# iorx65n register map
Registers are 8-bit, access not given, no defined reset value unless marked. A register's access mark holds for its fields unless they carry their own. Addresses are absolute; registers are grouped by the start of their names; [hi:lo] are bit positions.

## SFR (part 5 of 7)
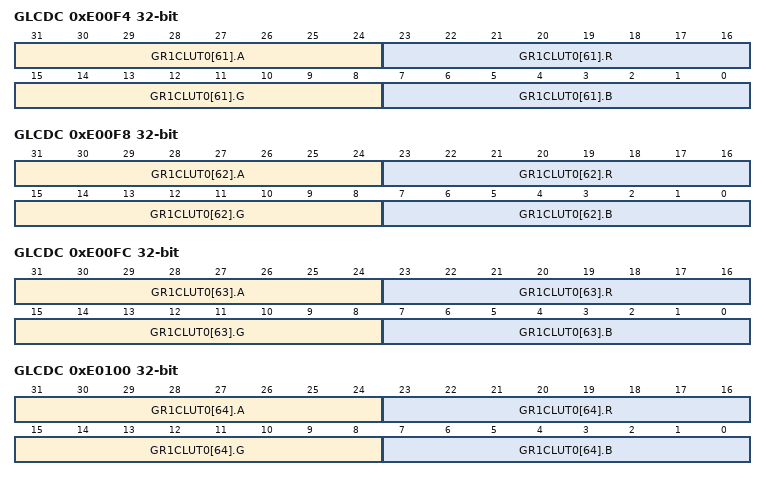
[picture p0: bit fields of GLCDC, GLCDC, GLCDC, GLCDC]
0xE00F4 GLCDC 32-bit
  [31:24] GR1CLUT0[61].A, [23:16] GR1CLUT0[61].R, [15:8] GR1CLUT0[61].G, [7:0] GR1CLUT0[61].B
0xE00F8 GLCDC 32-bit
  [31:24] GR1CLUT0[62].A, [23:16] GR1CLUT0[62].R, [15:8] GR1CLUT0[62].G, [7:0] GR1CLUT0[62].B
0xE00FC GLCDC 32-bit
  [31:24] GR1CLUT0[63].A, [23:16] GR1CLUT0[63].R, [15:8] GR1CLUT0[63].G, [7:0] GR1CLUT0[63].B
0xE0100 GLCDC 32-bit
  [31:24] GR1CLUT0[64].A, [23:16] GR1CLUT0[64].R, [15:8] GR1CLUT0[64].G, [7:0] GR1CLUT0[64].B
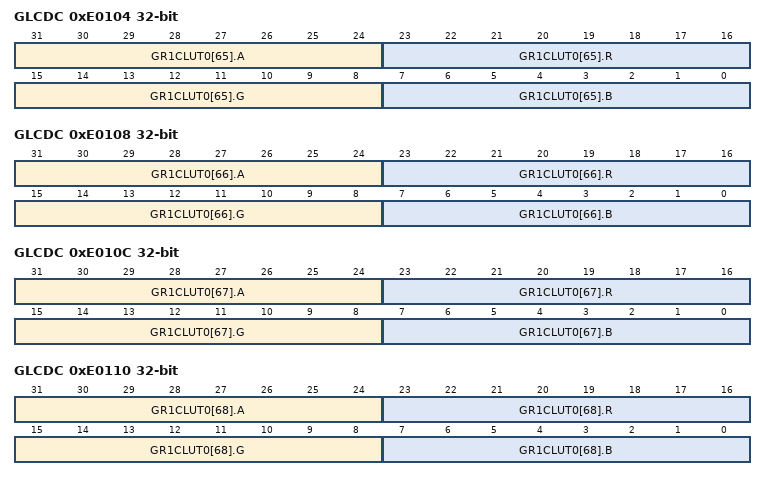
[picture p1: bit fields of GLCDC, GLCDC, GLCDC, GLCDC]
0xE0104 GLCDC 32-bit
  [31:24] GR1CLUT0[65].A, [23:16] GR1CLUT0[65].R, [15:8] GR1CLUT0[65].G, [7:0] GR1CLUT0[65].B
0xE0108 GLCDC 32-bit
  [31:24] GR1CLUT0[66].A, [23:16] GR1CLUT0[66].R, [15:8] GR1CLUT0[66].G, [7:0] GR1CLUT0[66].B
0xE010C GLCDC 32-bit
  [31:24] GR1CLUT0[67].A, [23:16] GR1CLUT0[67].R, [15:8] GR1CLUT0[67].G, [7:0] GR1CLUT0[67].B
0xE0110 GLCDC 32-bit
  [31:24] GR1CLUT0[68].A, [23:16] GR1CLUT0[68].R, [15:8] GR1CLUT0[68].G, [7:0] GR1CLUT0[68].B
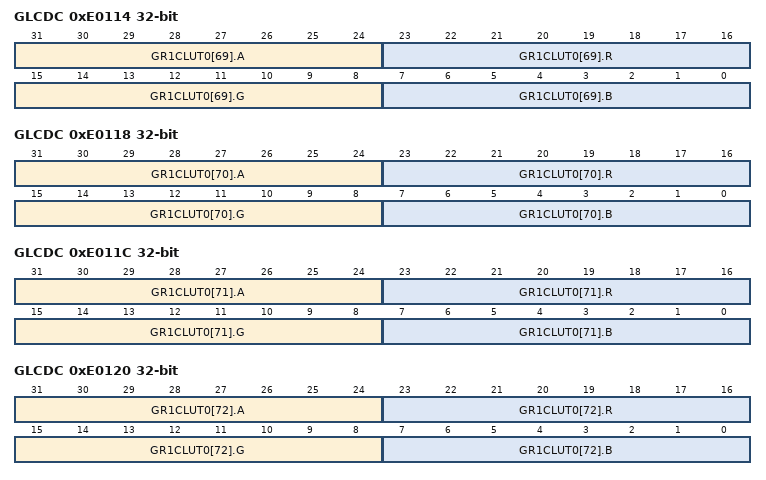
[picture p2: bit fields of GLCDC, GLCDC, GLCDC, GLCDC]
0xE0114 GLCDC 32-bit
  [31:24] GR1CLUT0[69].A, [23:16] GR1CLUT0[69].R, [15:8] GR1CLUT0[69].G, [7:0] GR1CLUT0[69].B
0xE0118 GLCDC 32-bit
  [31:24] GR1CLUT0[70].A, [23:16] GR1CLUT0[70].R, [15:8] GR1CLUT0[70].G, [7:0] GR1CLUT0[70].B
0xE011C GLCDC 32-bit
  [31:24] GR1CLUT0[71].A, [23:16] GR1CLUT0[71].R, [15:8] GR1CLUT0[71].G, [7:0] GR1CLUT0[71].B
0xE0120 GLCDC 32-bit
  [31:24] GR1CLUT0[72].A, [23:16] GR1CLUT0[72].R, [15:8] GR1CLUT0[72].G, [7:0] GR1CLUT0[72].B
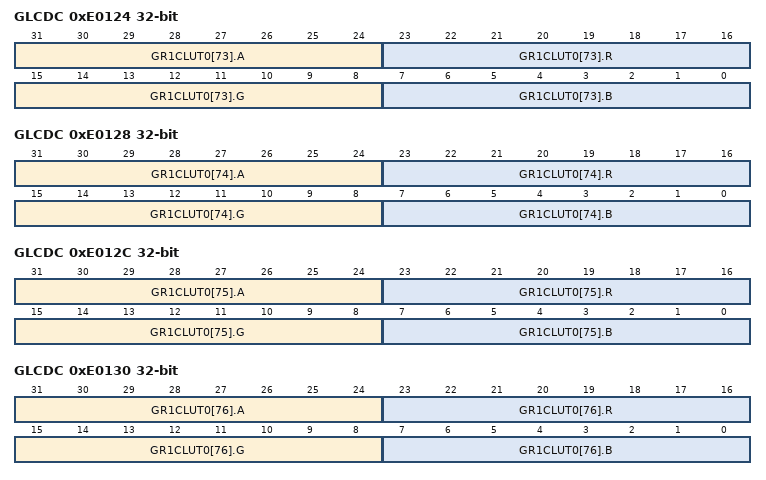
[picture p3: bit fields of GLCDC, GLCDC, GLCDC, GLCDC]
0xE0124 GLCDC 32-bit
  [31:24] GR1CLUT0[73].A, [23:16] GR1CLUT0[73].R, [15:8] GR1CLUT0[73].G, [7:0] GR1CLUT0[73].B
0xE0128 GLCDC 32-bit
  [31:24] GR1CLUT0[74].A, [23:16] GR1CLUT0[74].R, [15:8] GR1CLUT0[74].G, [7:0] GR1CLUT0[74].B
0xE012C GLCDC 32-bit
  [31:24] GR1CLUT0[75].A, [23:16] GR1CLUT0[75].R, [15:8] GR1CLUT0[75].G, [7:0] GR1CLUT0[75].B
0xE0130 GLCDC 32-bit
  [31:24] GR1CLUT0[76].A, [23:16] GR1CLUT0[76].R, [15:8] GR1CLUT0[76].G, [7:0] GR1CLUT0[76].B
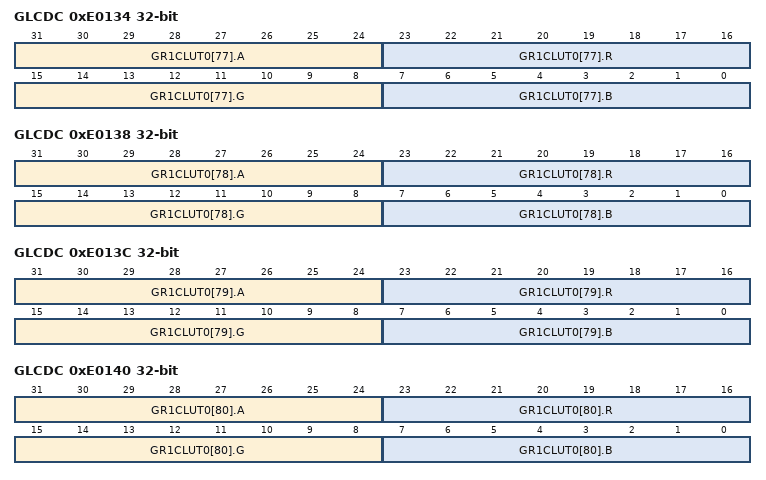
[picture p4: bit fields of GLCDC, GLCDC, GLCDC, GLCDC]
0xE0134 GLCDC 32-bit
  [31:24] GR1CLUT0[77].A, [23:16] GR1CLUT0[77].R, [15:8] GR1CLUT0[77].G, [7:0] GR1CLUT0[77].B
0xE0138 GLCDC 32-bit
  [31:24] GR1CLUT0[78].A, [23:16] GR1CLUT0[78].R, [15:8] GR1CLUT0[78].G, [7:0] GR1CLUT0[78].B
0xE013C GLCDC 32-bit
  [31:24] GR1CLUT0[79].A, [23:16] GR1CLUT0[79].R, [15:8] GR1CLUT0[79].G, [7:0] GR1CLUT0[79].B
0xE0140 GLCDC 32-bit
  [31:24] GR1CLUT0[80].A, [23:16] GR1CLUT0[80].R, [15:8] GR1CLUT0[80].G, [7:0] GR1CLUT0[80].B
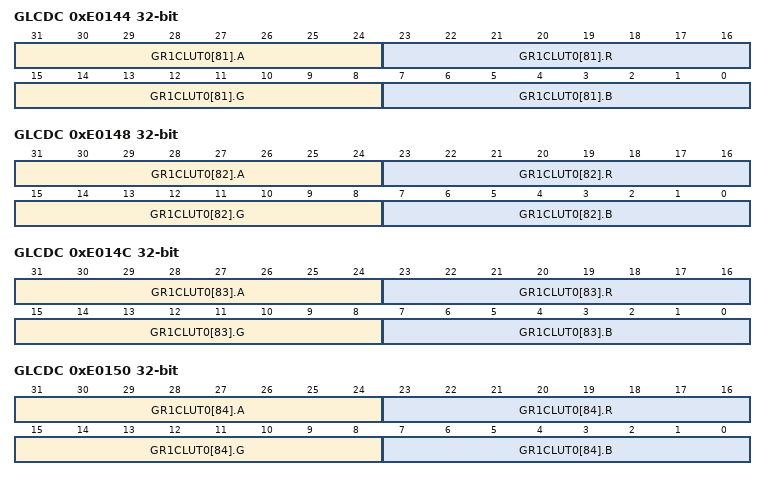
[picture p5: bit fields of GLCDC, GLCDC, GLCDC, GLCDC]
0xE0144 GLCDC 32-bit
  [31:24] GR1CLUT0[81].A, [23:16] GR1CLUT0[81].R, [15:8] GR1CLUT0[81].G, [7:0] GR1CLUT0[81].B
0xE0148 GLCDC 32-bit
  [31:24] GR1CLUT0[82].A, [23:16] GR1CLUT0[82].R, [15:8] GR1CLUT0[82].G, [7:0] GR1CLUT0[82].B
0xE014C GLCDC 32-bit
  [31:24] GR1CLUT0[83].A, [23:16] GR1CLUT0[83].R, [15:8] GR1CLUT0[83].G, [7:0] GR1CLUT0[83].B
0xE0150 GLCDC 32-bit
  [31:24] GR1CLUT0[84].A, [23:16] GR1CLUT0[84].R, [15:8] GR1CLUT0[84].G, [7:0] GR1CLUT0[84].B
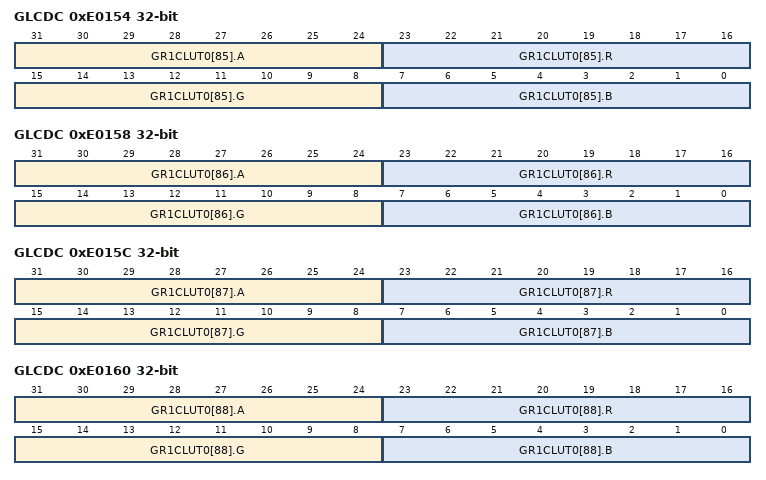
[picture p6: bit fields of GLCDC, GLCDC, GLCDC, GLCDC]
0xE0154 GLCDC 32-bit
  [31:24] GR1CLUT0[85].A, [23:16] GR1CLUT0[85].R, [15:8] GR1CLUT0[85].G, [7:0] GR1CLUT0[85].B
0xE0158 GLCDC 32-bit
  [31:24] GR1CLUT0[86].A, [23:16] GR1CLUT0[86].R, [15:8] GR1CLUT0[86].G, [7:0] GR1CLUT0[86].B
0xE015C GLCDC 32-bit
  [31:24] GR1CLUT0[87].A, [23:16] GR1CLUT0[87].R, [15:8] GR1CLUT0[87].G, [7:0] GR1CLUT0[87].B
0xE0160 GLCDC 32-bit
  [31:24] GR1CLUT0[88].A, [23:16] GR1CLUT0[88].R, [15:8] GR1CLUT0[88].G, [7:0] GR1CLUT0[88].B
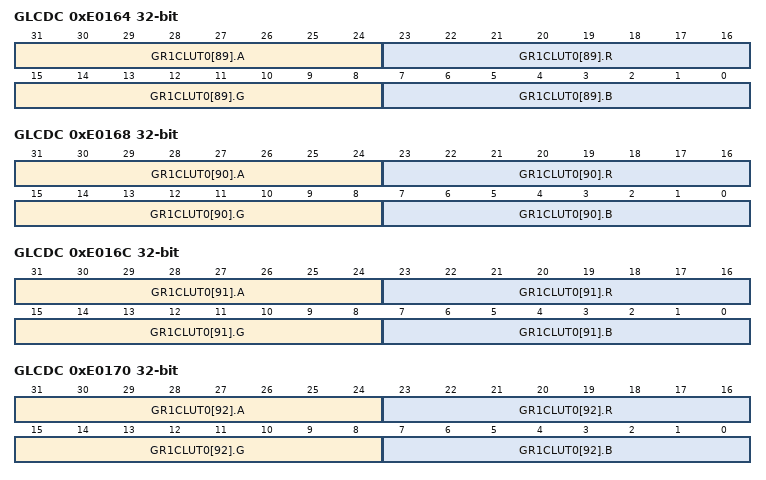
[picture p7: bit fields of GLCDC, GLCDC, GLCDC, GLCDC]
0xE0164 GLCDC 32-bit
  [31:24] GR1CLUT0[89].A, [23:16] GR1CLUT0[89].R, [15:8] GR1CLUT0[89].G, [7:0] GR1CLUT0[89].B
0xE0168 GLCDC 32-bit
  [31:24] GR1CLUT0[90].A, [23:16] GR1CLUT0[90].R, [15:8] GR1CLUT0[90].G, [7:0] GR1CLUT0[90].B
0xE016C GLCDC 32-bit
  [31:24] GR1CLUT0[91].A, [23:16] GR1CLUT0[91].R, [15:8] GR1CLUT0[91].G, [7:0] GR1CLUT0[91].B
0xE0170 GLCDC 32-bit
  [31:24] GR1CLUT0[92].A, [23:16] GR1CLUT0[92].R, [15:8] GR1CLUT0[92].G, [7:0] GR1CLUT0[92].B
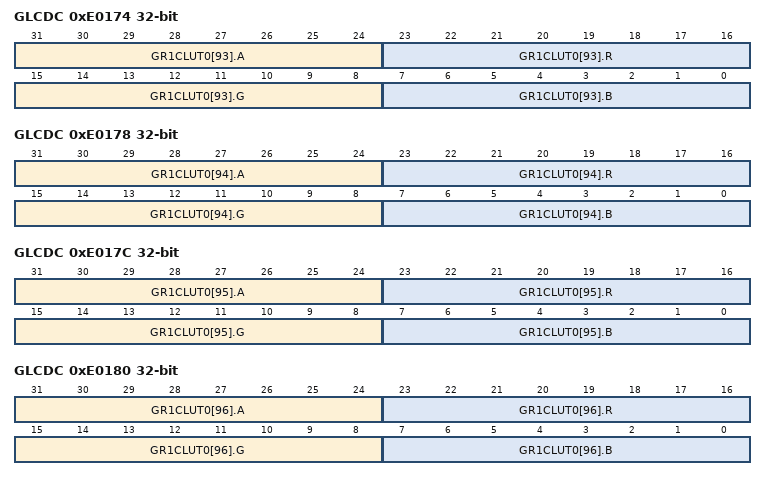
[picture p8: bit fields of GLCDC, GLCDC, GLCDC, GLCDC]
0xE0174 GLCDC 32-bit
  [31:24] GR1CLUT0[93].A, [23:16] GR1CLUT0[93].R, [15:8] GR1CLUT0[93].G, [7:0] GR1CLUT0[93].B
0xE0178 GLCDC 32-bit
  [31:24] GR1CLUT0[94].A, [23:16] GR1CLUT0[94].R, [15:8] GR1CLUT0[94].G, [7:0] GR1CLUT0[94].B
0xE017C GLCDC 32-bit
  [31:24] GR1CLUT0[95].A, [23:16] GR1CLUT0[95].R, [15:8] GR1CLUT0[95].G, [7:0] GR1CLUT0[95].B
0xE0180 GLCDC 32-bit
  [31:24] GR1CLUT0[96].A, [23:16] GR1CLUT0[96].R, [15:8] GR1CLUT0[96].G, [7:0] GR1CLUT0[96].B
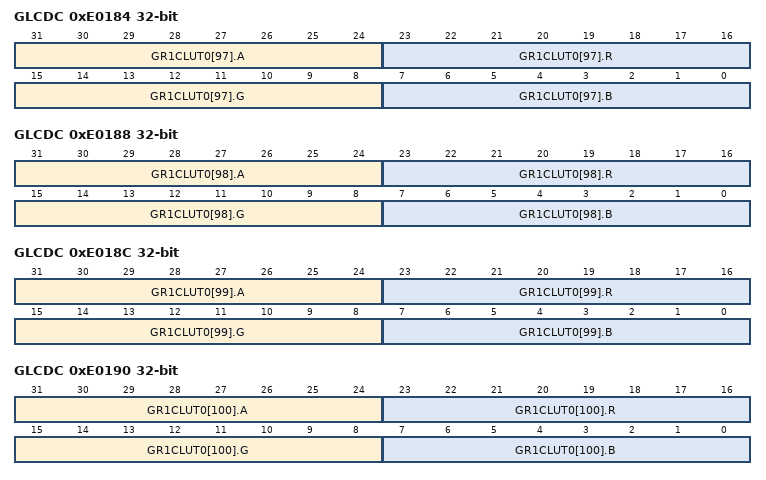
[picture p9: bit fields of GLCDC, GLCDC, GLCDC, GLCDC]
0xE0184 GLCDC 32-bit
  [31:24] GR1CLUT0[97].A, [23:16] GR1CLUT0[97].R, [15:8] GR1CLUT0[97].G, [7:0] GR1CLUT0[97].B
0xE0188 GLCDC 32-bit
  [31:24] GR1CLUT0[98].A, [23:16] GR1CLUT0[98].R, [15:8] GR1CLUT0[98].G, [7:0] GR1CLUT0[98].B
0xE018C GLCDC 32-bit
  [31:24] GR1CLUT0[99].A, [23:16] GR1CLUT0[99].R, [15:8] GR1CLUT0[99].G, [7:0] GR1CLUT0[99].B
0xE0190 GLCDC 32-bit
  [31:24] GR1CLUT0[100].A, [23:16] GR1CLUT0[100].R, [15:8] GR1CLUT0[100].G, [7:0] GR1CLUT0[100].B
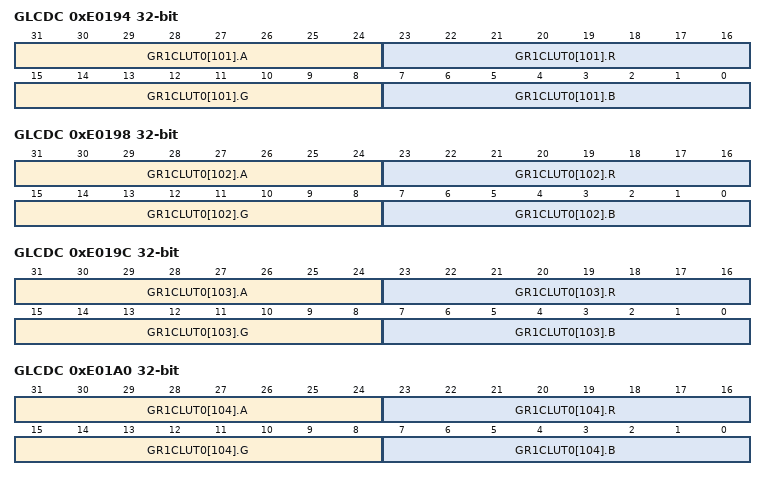
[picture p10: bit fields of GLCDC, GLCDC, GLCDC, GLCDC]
0xE0194 GLCDC 32-bit
  [31:24] GR1CLUT0[101].A, [23:16] GR1CLUT0[101].R, [15:8] GR1CLUT0[101].G, [7:0] GR1CLUT0[101].B
0xE0198 GLCDC 32-bit
  [31:24] GR1CLUT0[102].A, [23:16] GR1CLUT0[102].R, [15:8] GR1CLUT0[102].G, [7:0] GR1CLUT0[102].B
0xE019C GLCDC 32-bit
  [31:24] GR1CLUT0[103].A, [23:16] GR1CLUT0[103].R, [15:8] GR1CLUT0[103].G, [7:0] GR1CLUT0[103].B
0xE01A0 GLCDC 32-bit
  [31:24] GR1CLUT0[104].A, [23:16] GR1CLUT0[104].R, [15:8] GR1CLUT0[104].G, [7:0] GR1CLUT0[104].B
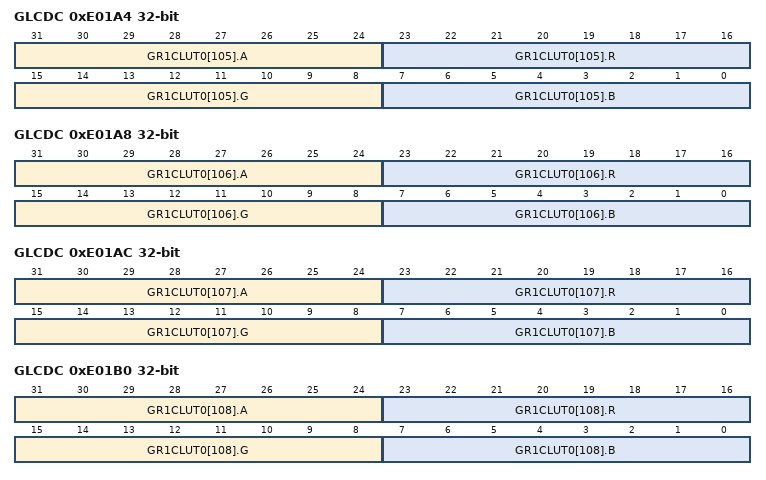
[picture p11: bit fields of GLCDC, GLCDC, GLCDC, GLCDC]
0xE01A4 GLCDC 32-bit
  [31:24] GR1CLUT0[105].A, [23:16] GR1CLUT0[105].R, [15:8] GR1CLUT0[105].G, [7:0] GR1CLUT0[105].B
0xE01A8 GLCDC 32-bit
  [31:24] GR1CLUT0[106].A, [23:16] GR1CLUT0[106].R, [15:8] GR1CLUT0[106].G, [7:0] GR1CLUT0[106].B
0xE01AC GLCDC 32-bit
  [31:24] GR1CLUT0[107].A, [23:16] GR1CLUT0[107].R, [15:8] GR1CLUT0[107].G, [7:0] GR1CLUT0[107].B
0xE01B0 GLCDC 32-bit
  [31:24] GR1CLUT0[108].A, [23:16] GR1CLUT0[108].R, [15:8] GR1CLUT0[108].G, [7:0] GR1CLUT0[108].B
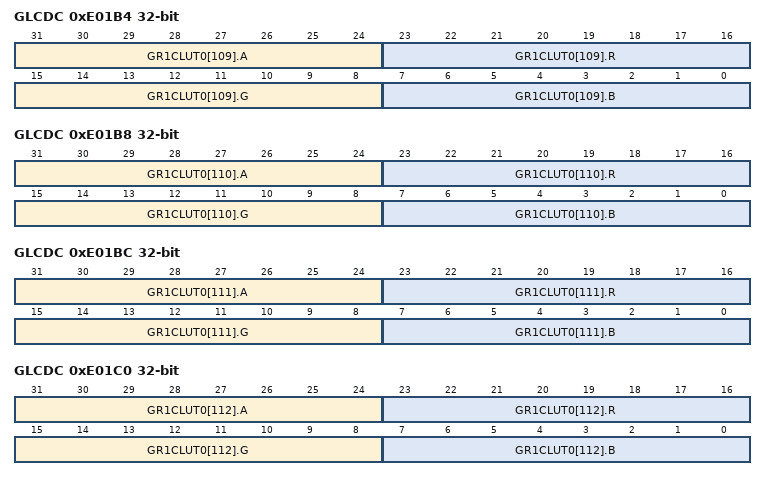
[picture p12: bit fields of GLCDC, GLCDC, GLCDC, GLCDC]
0xE01B4 GLCDC 32-bit
  [31:24] GR1CLUT0[109].A, [23:16] GR1CLUT0[109].R, [15:8] GR1CLUT0[109].G, [7:0] GR1CLUT0[109].B
0xE01B8 GLCDC 32-bit
  [31:24] GR1CLUT0[110].A, [23:16] GR1CLUT0[110].R, [15:8] GR1CLUT0[110].G, [7:0] GR1CLUT0[110].B
0xE01BC GLCDC 32-bit
  [31:24] GR1CLUT0[111].A, [23:16] GR1CLUT0[111].R, [15:8] GR1CLUT0[111].G, [7:0] GR1CLUT0[111].B
0xE01C0 GLCDC 32-bit
  [31:24] GR1CLUT0[112].A, [23:16] GR1CLUT0[112].R, [15:8] GR1CLUT0[112].G, [7:0] GR1CLUT0[112].B
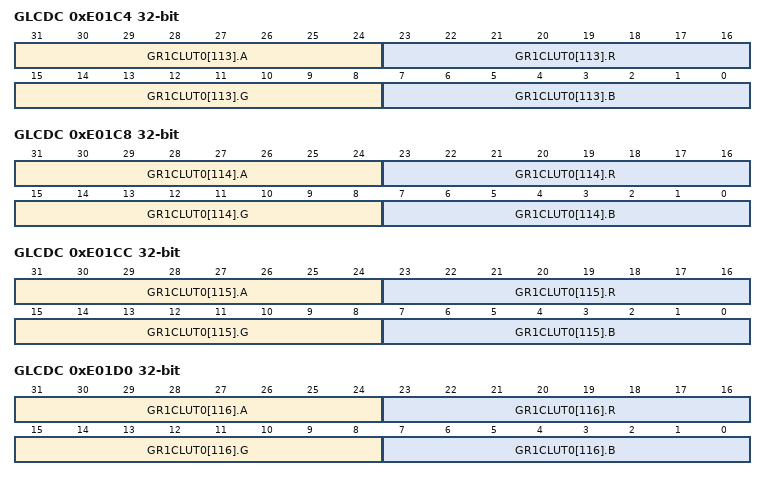
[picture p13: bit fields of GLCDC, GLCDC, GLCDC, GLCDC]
0xE01C4 GLCDC 32-bit
  [31:24] GR1CLUT0[113].A, [23:16] GR1CLUT0[113].R, [15:8] GR1CLUT0[113].G, [7:0] GR1CLUT0[113].B
0xE01C8 GLCDC 32-bit
  [31:24] GR1CLUT0[114].A, [23:16] GR1CLUT0[114].R, [15:8] GR1CLUT0[114].G, [7:0] GR1CLUT0[114].B
0xE01CC GLCDC 32-bit
  [31:24] GR1CLUT0[115].A, [23:16] GR1CLUT0[115].R, [15:8] GR1CLUT0[115].G, [7:0] GR1CLUT0[115].B
0xE01D0 GLCDC 32-bit
  [31:24] GR1CLUT0[116].A, [23:16] GR1CLUT0[116].R, [15:8] GR1CLUT0[116].G, [7:0] GR1CLUT0[116].B
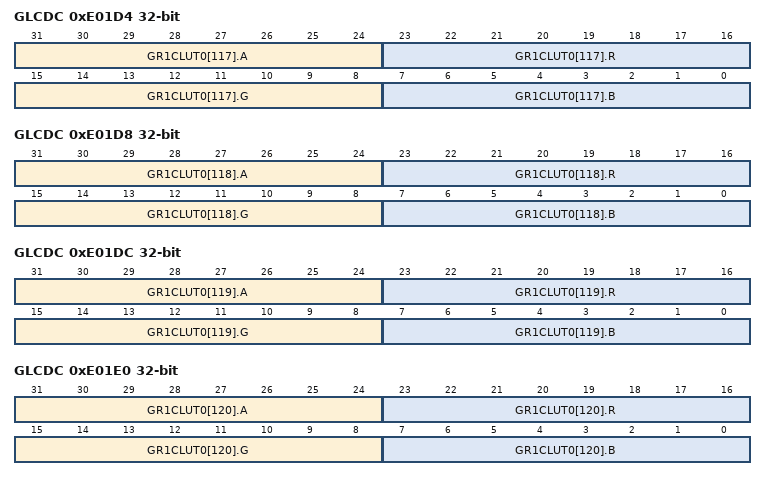
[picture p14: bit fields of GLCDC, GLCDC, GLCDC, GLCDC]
0xE01D4 GLCDC 32-bit
  [31:24] GR1CLUT0[117].A, [23:16] GR1CLUT0[117].R, [15:8] GR1CLUT0[117].G, [7:0] GR1CLUT0[117].B
0xE01D8 GLCDC 32-bit
  [31:24] GR1CLUT0[118].A, [23:16] GR1CLUT0[118].R, [15:8] GR1CLUT0[118].G, [7:0] GR1CLUT0[118].B
0xE01DC GLCDC 32-bit
  [31:24] GR1CLUT0[119].A, [23:16] GR1CLUT0[119].R, [15:8] GR1CLUT0[119].G, [7:0] GR1CLUT0[119].B
0xE01E0 GLCDC 32-bit
  [31:24] GR1CLUT0[120].A, [23:16] GR1CLUT0[120].R, [15:8] GR1CLUT0[120].G, [7:0] GR1CLUT0[120].B
0xE01E4 GLCDC 32-bit
  [31:24] GR1CLUT0[121].A, [23:16] GR1CLUT0[121].R, [15:8] GR1CLUT0[121].G, [7:0] GR1CLUT0[121].B
0xE01E8 GLCDC 32-bit
  [31:24] GR1CLUT0[122].A, [23:16] GR1CLUT0[122].R, [15:8] GR1CLUT0[122].G, [7:0] GR1CLUT0[122].B
0xE01EC GLCDC 32-bit
  [31:24] GR1CLUT0[123].A, [23:16] GR1CLUT0[123].R, [15:8] GR1CLUT0[123].G, [7:0] GR1CLUT0[123].B
0xE01F0 GLCDC 32-bit
  [31:24] GR1CLUT0[124].A, [23:16] GR1CLUT0[124].R, [15:8] GR1CLUT0[124].G, [7:0] GR1CLUT0[124].B
0xE01F4 GLCDC 32-bit
  [31:24] GR1CLUT0[125].A, [23:16] GR1CLUT0[125].R, [15:8] GR1CLUT0[125].G, [7:0] GR1CLUT0[125].B
0xE01F8 GLCDC 32-bit
  [31:24] GR1CLUT0[126].A, [23:16] GR1CLUT0[126].R, [15:8] GR1CLUT0[126].G, [7:0] GR1CLUT0[126].B
0xE01FC GLCDC 32-bit
  [31:24] GR1CLUT0[127].A, [23:16] GR1CLUT0[127].R, [15:8] GR1CLUT0[127].G, [7:0] GR1CLUT0[127].B
0xE0200 GLCDC 32-bit
  [31:24] GR1CLUT0[128].A, [23:16] GR1CLUT0[128].R, [15:8] GR1CLUT0[128].G, [7:0] GR1CLUT0[128].B
0xE0204 GLCDC 32-bit
  [31:24] GR1CLUT0[129].A, [23:16] GR1CLUT0[129].R, [15:8] GR1CLUT0[129].G, [7:0] GR1CLUT0[129].B
0xE0208 GLCDC 32-bit
  [31:24] GR1CLUT0[130].A, [23:16] GR1CLUT0[130].R, [15:8] GR1CLUT0[130].G, [7:0] GR1CLUT0[130].B
0xE020C GLCDC 32-bit
  [31:24] GR1CLUT0[131].A, [23:16] GR1CLUT0[131].R, [15:8] GR1CLUT0[131].G, [7:0] GR1CLUT0[131].B
0xE0210 GLCDC 32-bit
  [31:24] GR1CLUT0[132].A, [23:16] GR1CLUT0[132].R, [15:8] GR1CLUT0[132].G, [7:0] GR1CLUT0[132].B
0xE0214 GLCDC 32-bit
  [31:24] GR1CLUT0[133].A, [23:16] GR1CLUT0[133].R, [15:8] GR1CLUT0[133].G, [7:0] GR1CLUT0[133].B
0xE0218 GLCDC 32-bit
  [31:24] GR1CLUT0[134].A, [23:16] GR1CLUT0[134].R, [15:8] GR1CLUT0[134].G, [7:0] GR1CLUT0[134].B
0xE021C GLCDC 32-bit
  [31:24] GR1CLUT0[135].A, [23:16] GR1CLUT0[135].R, [15:8] GR1CLUT0[135].G, [7:0] GR1CLUT0[135].B
0xE0220 GLCDC 32-bit
  [31:24] GR1CLUT0[136].A, [23:16] GR1CLUT0[136].R, [15:8] GR1CLUT0[136].G, [7:0] GR1CLUT0[136].B
0xE0224 GLCDC 32-bit
  [31:24] GR1CLUT0[137].A, [23:16] GR1CLUT0[137].R, [15:8] GR1CLUT0[137].G, [7:0] GR1CLUT0[137].B
0xE0228 GLCDC 32-bit
  [31:24] GR1CLUT0[138].A, [23:16] GR1CLUT0[138].R, [15:8] GR1CLUT0[138].G, [7:0] GR1CLUT0[138].B
0xE022C GLCDC 32-bit
  [31:24] GR1CLUT0[139].A, [23:16] GR1CLUT0[139].R, [15:8] GR1CLUT0[139].G, [7:0] GR1CLUT0[139].B
0xE0230 GLCDC 32-bit
  [31:24] GR1CLUT0[140].A, [23:16] GR1CLUT0[140].R, [15:8] GR1CLUT0[140].G, [7:0] GR1CLUT0[140].B
0xE0234 GLCDC 32-bit
  [31:24] GR1CLUT0[141].A, [23:16] GR1CLUT0[141].R, [15:8] GR1CLUT0[141].G, [7:0] GR1CLUT0[141].B
0xE0238 GLCDC 32-bit
  [31:24] GR1CLUT0[142].A, [23:16] GR1CLUT0[142].R, [15:8] GR1CLUT0[142].G, [7:0] GR1CLUT0[142].B
0xE023C GLCDC 32-bit
  [31:24] GR1CLUT0[143].A, [23:16] GR1CLUT0[143].R, [15:8] GR1CLUT0[143].G, [7:0] GR1CLUT0[143].B
0xE0240 GLCDC 32-bit
  [31:24] GR1CLUT0[144].A, [23:16] GR1CLUT0[144].R, [15:8] GR1CLUT0[144].G, [7:0] GR1CLUT0[144].B
0xE0244 GLCDC 32-bit
  [31:24] GR1CLUT0[145].A, [23:16] GR1CLUT0[145].R, [15:8] GR1CLUT0[145].G, [7:0] GR1CLUT0[145].B
0xE0248 GLCDC 32-bit
  [31:24] GR1CLUT0[146].A, [23:16] GR1CLUT0[146].R, [15:8] GR1CLUT0[146].G, [7:0] GR1CLUT0[146].B
0xE024C GLCDC 32-bit
  [31:24] GR1CLUT0[147].A, [23:16] GR1CLUT0[147].R, [15:8] GR1CLUT0[147].G, [7:0] GR1CLUT0[147].B
0xE0250 GLCDC 32-bit
  [31:24] GR1CLUT0[148].A, [23:16] GR1CLUT0[148].R, [15:8] GR1CLUT0[148].G, [7:0] GR1CLUT0[148].B
0xE0254 GLCDC 32-bit
  [31:24] GR1CLUT0[149].A, [23:16] GR1CLUT0[149].R, [15:8] GR1CLUT0[149].G, [7:0] GR1CLUT0[149].B
0xE0258 GLCDC 32-bit
  [31:24] GR1CLUT0[150].A, [23:16] GR1CLUT0[150].R, [15:8] GR1CLUT0[150].G, [7:0] GR1CLUT0[150].B
0xE025C GLCDC 32-bit
  [31:24] GR1CLUT0[151].A, [23:16] GR1CLUT0[151].R, [15:8] GR1CLUT0[151].G, [7:0] GR1CLUT0[151].B
0xE0260 GLCDC 32-bit
  [31:24] GR1CLUT0[152].A, [23:16] GR1CLUT0[152].R, [15:8] GR1CLUT0[152].G, [7:0] GR1CLUT0[152].B
0xE0264 GLCDC 32-bit
  [31:24] GR1CLUT0[153].A, [23:16] GR1CLUT0[153].R, [15:8] GR1CLUT0[153].G, [7:0] GR1CLUT0[153].B
0xE0268 GLCDC 32-bit
  [31:24] GR1CLUT0[154].A, [23:16] GR1CLUT0[154].R, [15:8] GR1CLUT0[154].G, [7:0] GR1CLUT0[154].B
0xE026C GLCDC 32-bit
  [31:24] GR1CLUT0[155].A, [23:16] GR1CLUT0[155].R, [15:8] GR1CLUT0[155].G, [7:0] GR1CLUT0[155].B
0xE0270 GLCDC 32-bit
  [31:24] GR1CLUT0[156].A, [23:16] GR1CLUT0[156].R, [15:8] GR1CLUT0[156].G, [7:0] GR1CLUT0[156].B
0xE0274 GLCDC 32-bit
  [31:24] GR1CLUT0[157].A, [23:16] GR1CLUT0[157].R, [15:8] GR1CLUT0[157].G, [7:0] GR1CLUT0[157].B
0xE0278 GLCDC 32-bit
  [31:24] GR1CLUT0[158].A, [23:16] GR1CLUT0[158].R, [15:8] GR1CLUT0[158].G, [7:0] GR1CLUT0[158].B
0xE027C GLCDC 32-bit
  [31:24] GR1CLUT0[159].A, [23:16] GR1CLUT0[159].R, [15:8] GR1CLUT0[159].G, [7:0] GR1CLUT0[159].B
0xE0280 GLCDC 32-bit
  [31:24] GR1CLUT0[160].A, [23:16] GR1CLUT0[160].R, [15:8] GR1CLUT0[160].G, [7:0] GR1CLUT0[160].B
0xE0284 GLCDC 32-bit
  [31:24] GR1CLUT0[161].A, [23:16] GR1CLUT0[161].R, [15:8] GR1CLUT0[161].G, [7:0] GR1CLUT0[161].B
0xE0288 GLCDC 32-bit
  [31:24] GR1CLUT0[162].A, [23:16] GR1CLUT0[162].R, [15:8] GR1CLUT0[162].G, [7:0] GR1CLUT0[162].B
0xE028C GLCDC 32-bit
  [31:24] GR1CLUT0[163].A, [23:16] GR1CLUT0[163].R, [15:8] GR1CLUT0[163].G, [7:0] GR1CLUT0[163].B
0xE0290 GLCDC 32-bit
  [31:24] GR1CLUT0[164].A, [23:16] GR1CLUT0[164].R, [15:8] GR1CLUT0[164].G, [7:0] GR1CLUT0[164].B
0xE0294 GLCDC 32-bit
  [31:24] GR1CLUT0[165].A, [23:16] GR1CLUT0[165].R, [15:8] GR1CLUT0[165].G, [7:0] GR1CLUT0[165].B
0xE0298 GLCDC 32-bit
  [31:24] GR1CLUT0[166].A, [23:16] GR1CLUT0[166].R, [15:8] GR1CLUT0[166].G, [7:0] GR1CLUT0[166].B
0xE029C GLCDC 32-bit
  [31:24] GR1CLUT0[167].A, [23:16] GR1CLUT0[167].R, [15:8] GR1CLUT0[167].G, [7:0] GR1CLUT0[167].B
0xE02A0 GLCDC 32-bit
  [31:24] GR1CLUT0[168].A, [23:16] GR1CLUT0[168].R, [15:8] GR1CLUT0[168].G, [7:0] GR1CLUT0[168].B
0xE02A4 GLCDC 32-bit
  [31:24] GR1CLUT0[169].A, [23:16] GR1CLUT0[169].R, [15:8] GR1CLUT0[169].G, [7:0] GR1CLUT0[169].B
0xE02A8 GLCDC 32-bit
  [31:24] GR1CLUT0[170].A, [23:16] GR1CLUT0[170].R, [15:8] GR1CLUT0[170].G, [7:0] GR1CLUT0[170].B
0xE02AC GLCDC 32-bit
  [31:24] GR1CLUT0[171].A, [23:16] GR1CLUT0[171].R, [15:8] GR1CLUT0[171].G, [7:0] GR1CLUT0[171].B
0xE02B0 GLCDC 32-bit
  [31:24] GR1CLUT0[172].A, [23:16] GR1CLUT0[172].R, [15:8] GR1CLUT0[172].G, [7:0] GR1CLUT0[172].B
0xE02B4 GLCDC 32-bit
  [31:24] GR1CLUT0[173].A, [23:16] GR1CLUT0[173].R, [15:8] GR1CLUT0[173].G, [7:0] GR1CLUT0[173].B
0xE02B8 GLCDC 32-bit
  [31:24] GR1CLUT0[174].A, [23:16] GR1CLUT0[174].R, [15:8] GR1CLUT0[174].G, [7:0] GR1CLUT0[174].B
0xE02BC GLCDC 32-bit
  [31:24] GR1CLUT0[175].A, [23:16] GR1CLUT0[175].R, [15:8] GR1CLUT0[175].G, [7:0] GR1CLUT0[175].B
0xE02C0 GLCDC 32-bit
  [31:24] GR1CLUT0[176].A, [23:16] GR1CLUT0[176].R, [15:8] GR1CLUT0[176].G, [7:0] GR1CLUT0[176].B
0xE02C4 GLCDC 32-bit
  [31:24] GR1CLUT0[177].A, [23:16] GR1CLUT0[177].R, [15:8] GR1CLUT0[177].G, [7:0] GR1CLUT0[177].B
0xE02C8 GLCDC 32-bit
  [31:24] GR1CLUT0[178].A, [23:16] GR1CLUT0[178].R, [15:8] GR1CLUT0[178].G, [7:0] GR1CLUT0[178].B
0xE02CC GLCDC 32-bit
  [31:24] GR1CLUT0[179].A, [23:16] GR1CLUT0[179].R, [15:8] GR1CLUT0[179].G, [7:0] GR1CLUT0[179].B
0xE02D0 GLCDC 32-bit
  [31:24] GR1CLUT0[180].A, [23:16] GR1CLUT0[180].R, [15:8] GR1CLUT0[180].G, [7:0] GR1CLUT0[180].B
0xE02D4 GLCDC 32-bit
  [31:24] GR1CLUT0[181].A, [23:16] GR1CLUT0[181].R, [15:8] GR1CLUT0[181].G, [7:0] GR1CLUT0[181].B
0xE02D8 GLCDC 32-bit
  [31:24] GR1CLUT0[182].A, [23:16] GR1CLUT0[182].R, [15:8] GR1CLUT0[182].G, [7:0] GR1CLUT0[182].B
0xE02DC GLCDC 32-bit
  [31:24] GR1CLUT0[183].A, [23:16] GR1CLUT0[183].R, [15:8] GR1CLUT0[183].G, [7:0] GR1CLUT0[183].B
0xE02E0 GLCDC 32-bit
  [31:24] GR1CLUT0[184].A, [23:16] GR1CLUT0[184].R, [15:8] GR1CLUT0[184].G, [7:0] GR1CLUT0[184].B
0xE02E4 GLCDC 32-bit
  [31:24] GR1CLUT0[185].A, [23:16] GR1CLUT0[185].R, [15:8] GR1CLUT0[185].G, [7:0] GR1CLUT0[185].B
0xE02E8 GLCDC 32-bit
  [31:24] GR1CLUT0[186].A, [23:16] GR1CLUT0[186].R, [15:8] GR1CLUT0[186].G, [7:0] GR1CLUT0[186].B
0xE02EC GLCDC 32-bit
  [31:24] GR1CLUT0[187].A, [23:16] GR1CLUT0[187].R, [15:8] GR1CLUT0[187].G, [7:0] GR1CLUT0[187].B
0xE02F0 GLCDC 32-bit
  [31:24] GR1CLUT0[188].A, [23:16] GR1CLUT0[188].R, [15:8] GR1CLUT0[188].G, [7:0] GR1CLUT0[188].B
0xE02F4 GLCDC 32-bit
  [31:24] GR1CLUT0[189].A, [23:16] GR1CLUT0[189].R, [15:8] GR1CLUT0[189].G, [7:0] GR1CLUT0[189].B
0xE02F8 GLCDC 32-bit
  [31:24] GR1CLUT0[190].A, [23:16] GR1CLUT0[190].R, [15:8] GR1CLUT0[190].G, [7:0] GR1CLUT0[190].B
0xE02FC GLCDC 32-bit
  [31:24] GR1CLUT0[191].A, [23:16] GR1CLUT0[191].R, [15:8] GR1CLUT0[191].G, [7:0] GR1CLUT0[191].B
0xE0300 GLCDC 32-bit
  [31:24] GR1CLUT0[192].A, [23:16] GR1CLUT0[192].R, [15:8] GR1CLUT0[192].G, [7:0] GR1CLUT0[192].B
0xE0304 GLCDC 32-bit
  [31:24] GR1CLUT0[193].A, [23:16] GR1CLUT0[193].R, [15:8] GR1CLUT0[193].G, [7:0] GR1CLUT0[193].B
0xE0308 GLCDC 32-bit
  [31:24] GR1CLUT0[194].A, [23:16] GR1CLUT0[194].R, [15:8] GR1CLUT0[194].G, [7:0] GR1CLUT0[194].B
0xE030C GLCDC 32-bit
  [31:24] GR1CLUT0[195].A, [23:16] GR1CLUT0[195].R, [15:8] GR1CLUT0[195].G, [7:0] GR1CLUT0[195].B
0xE0310 GLCDC 32-bit
  [31:24] GR1CLUT0[196].A, [23:16] GR1CLUT0[196].R, [15:8] GR1CLUT0[196].G, [7:0] GR1CLUT0[196].B
0xE0314 GLCDC 32-bit
  [31:24] GR1CLUT0[197].A, [23:16] GR1CLUT0[197].R, [15:8] GR1CLUT0[197].G, [7:0] GR1CLUT0[197].B
0xE0318 GLCDC 32-bit
  [31:24] GR1CLUT0[198].A, [23:16] GR1CLUT0[198].R, [15:8] GR1CLUT0[198].G, [7:0] GR1CLUT0[198].B
0xE031C GLCDC 32-bit
  [31:24] GR1CLUT0[199].A, [23:16] GR1CLUT0[199].R, [15:8] GR1CLUT0[199].G, [7:0] GR1CLUT0[199].B
0xE0320 GLCDC 32-bit
  [31:24] GR1CLUT0[200].A, [23:16] GR1CLUT0[200].R, [15:8] GR1CLUT0[200].G, [7:0] GR1CLUT0[200].B
0xE0324 GLCDC 32-bit
  [31:24] GR1CLUT0[201].A, [23:16] GR1CLUT0[201].R, [15:8] GR1CLUT0[201].G, [7:0] GR1CLUT0[201].B
0xE0328 GLCDC 32-bit
  [31:24] GR1CLUT0[202].A, [23:16] GR1CLUT0[202].R, [15:8] GR1CLUT0[202].G, [7:0] GR1CLUT0[202].B
0xE032C GLCDC 32-bit
  [31:24] GR1CLUT0[203].A, [23:16] GR1CLUT0[203].R, [15:8] GR1CLUT0[203].G, [7:0] GR1CLUT0[203].B
0xE0330 GLCDC 32-bit
  [31:24] GR1CLUT0[204].A, [23:16] GR1CLUT0[204].R, [15:8] GR1CLUT0[204].G, [7:0] GR1CLUT0[204].B
0xE0334 GLCDC 32-bit
  [31:24] GR1CLUT0[205].A, [23:16] GR1CLUT0[205].R, [15:8] GR1CLUT0[205].G, [7:0] GR1CLUT0[205].B
0xE0338 GLCDC 32-bit
  [31:24] GR1CLUT0[206].A, [23:16] GR1CLUT0[206].R, [15:8] GR1CLUT0[206].G, [7:0] GR1CLUT0[206].B
0xE033C GLCDC 32-bit
  [31:24] GR1CLUT0[207].A, [23:16] GR1CLUT0[207].R, [15:8] GR1CLUT0[207].G, [7:0] GR1CLUT0[207].B
0xE0340 GLCDC 32-bit
  [31:24] GR1CLUT0[208].A, [23:16] GR1CLUT0[208].R, [15:8] GR1CLUT0[208].G, [7:0] GR1CLUT0[208].B
0xE0344 GLCDC 32-bit
  [31:24] GR1CLUT0[209].A, [23:16] GR1CLUT0[209].R, [15:8] GR1CLUT0[209].G, [7:0] GR1CLUT0[209].B
0xE0348 GLCDC 32-bit
  [31:24] GR1CLUT0[210].A, [23:16] GR1CLUT0[210].R, [15:8] GR1CLUT0[210].G, [7:0] GR1CLUT0[210].B
0xE034C GLCDC 32-bit
  [31:24] GR1CLUT0[211].A, [23:16] GR1CLUT0[211].R, [15:8] GR1CLUT0[211].G, [7:0] GR1CLUT0[211].B
0xE0350 GLCDC 32-bit
  [31:24] GR1CLUT0[212].A, [23:16] GR1CLUT0[212].R, [15:8] GR1CLUT0[212].G, [7:0] GR1CLUT0[212].B
0xE0354 GLCDC 32-bit
  [31:24] GR1CLUT0[213].A, [23:16] GR1CLUT0[213].R, [15:8] GR1CLUT0[213].G, [7:0] GR1CLUT0[213].B
0xE0358 GLCDC 32-bit
  [31:24] GR1CLUT0[214].A, [23:16] GR1CLUT0[214].R, [15:8] GR1CLUT0[214].G, [7:0] GR1CLUT0[214].B
0xE035C GLCDC 32-bit
  [31:24] GR1CLUT0[215].A, [23:16] GR1CLUT0[215].R, [15:8] GR1CLUT0[215].G, [7:0] GR1CLUT0[215].B
0xE0360 GLCDC 32-bit
  [31:24] GR1CLUT0[216].A, [23:16] GR1CLUT0[216].R, [15:8] GR1CLUT0[216].G, [7:0] GR1CLUT0[216].B
0xE0364 GLCDC 32-bit
  [31:24] GR1CLUT0[217].A, [23:16] GR1CLUT0[217].R, [15:8] GR1CLUT0[217].G, [7:0] GR1CLUT0[217].B
0xE0368 GLCDC 32-bit
  [31:24] GR1CLUT0[218].A, [23:16] GR1CLUT0[218].R, [15:8] GR1CLUT0[218].G, [7:0] GR1CLUT0[218].B
0xE036C GLCDC 32-bit
  [31:24] GR1CLUT0[219].A, [23:16] GR1CLUT0[219].R, [15:8] GR1CLUT0[219].G, [7:0] GR1CLUT0[219].B
0xE0370 GLCDC 32-bit
  [31:24] GR1CLUT0[220].A, [23:16] GR1CLUT0[220].R, [15:8] GR1CLUT0[220].G, [7:0] GR1CLUT0[220].B
0xE0374 GLCDC 32-bit
  [31:24] GR1CLUT0[221].A, [23:16] GR1CLUT0[221].R, [15:8] GR1CLUT0[221].G, [7:0] GR1CLUT0[221].B
0xE0378 GLCDC 32-bit
  [31:24] GR1CLUT0[222].A, [23:16] GR1CLUT0[222].R, [15:8] GR1CLUT0[222].G, [7:0] GR1CLUT0[222].B
0xE037C GLCDC 32-bit
  [31:24] GR1CLUT0[223].A, [23:16] GR1CLUT0[223].R, [15:8] GR1CLUT0[223].G, [7:0] GR1CLUT0[223].B
0xE0380 GLCDC 32-bit
  [31:24] GR1CLUT0[224].A, [23:16] GR1CLUT0[224].R, [15:8] GR1CLUT0[224].G, [7:0] GR1CLUT0[224].B
0xE0384 GLCDC 32-bit
  [31:24] GR1CLUT0[225].A, [23:16] GR1CLUT0[225].R, [15:8] GR1CLUT0[225].G, [7:0] GR1CLUT0[225].B
0xE0388 GLCDC 32-bit
  [31:24] GR1CLUT0[226].A, [23:16] GR1CLUT0[226].R, [15:8] GR1CLUT0[226].G, [7:0] GR1CLUT0[226].B
0xE038C GLCDC 32-bit
  [31:24] GR1CLUT0[227].A, [23:16] GR1CLUT0[227].R, [15:8] GR1CLUT0[227].G, [7:0] GR1CLUT0[227].B
0xE0390 GLCDC 32-bit
  [31:24] GR1CLUT0[228].A, [23:16] GR1CLUT0[228].R, [15:8] GR1CLUT0[228].G, [7:0] GR1CLUT0[228].B
0xE0394 GLCDC 32-bit
  [31:24] GR1CLUT0[229].A, [23:16] GR1CLUT0[229].R, [15:8] GR1CLUT0[229].G, [7:0] GR1CLUT0[229].B
0xE0398 GLCDC 32-bit
  [31:24] GR1CLUT0[230].A, [23:16] GR1CLUT0[230].R, [15:8] GR1CLUT0[230].G, [7:0] GR1CLUT0[230].B
0xE039C GLCDC 32-bit
  [31:24] GR1CLUT0[231].A, [23:16] GR1CLUT0[231].R, [15:8] GR1CLUT0[231].G, [7:0] GR1CLUT0[231].B
0xE03A0 GLCDC 32-bit
  [31:24] GR1CLUT0[232].A, [23:16] GR1CLUT0[232].R, [15:8] GR1CLUT0[232].G, [7:0] GR1CLUT0[232].B
0xE03A4 GLCDC 32-bit
  [31:24] GR1CLUT0[233].A, [23:16] GR1CLUT0[233].R, [15:8] GR1CLUT0[233].G, [7:0] GR1CLUT0[233].B
0xE03A8 GLCDC 32-bit
  [31:24] GR1CLUT0[234].A, [23:16] GR1CLUT0[234].R, [15:8] GR1CLUT0[234].G, [7:0] GR1CLUT0[234].B
0xE03AC GLCDC 32-bit
  [31:24] GR1CLUT0[235].A, [23:16] GR1CLUT0[235].R, [15:8] GR1CLUT0[235].G, [7:0] GR1CLUT0[235].B
0xE03B0 GLCDC 32-bit
  [31:24] GR1CLUT0[236].A, [23:16] GR1CLUT0[236].R, [15:8] GR1CLUT0[236].G, [7:0] GR1CLUT0[236].B
0xE03B4 GLCDC 32-bit
  [31:24] GR1CLUT0[237].A, [23:16] GR1CLUT0[237].R, [15:8] GR1CLUT0[237].G, [7:0] GR1CLUT0[237].B
0xE03B8 GLCDC 32-bit
  [31:24] GR1CLUT0[238].A, [23:16] GR1CLUT0[238].R, [15:8] GR1CLUT0[238].G, [7:0] GR1CLUT0[238].B
0xE03BC GLCDC 32-bit
  [31:24] GR1CLUT0[239].A, [23:16] GR1CLUT0[239].R, [15:8] GR1CLUT0[239].G, [7:0] GR1CLUT0[239].B
0xE03C0 GLCDC 32-bit
  [31:24] GR1CLUT0[240].A, [23:16] GR1CLUT0[240].R, [15:8] GR1CLUT0[240].G, [7:0] GR1CLUT0[240].B
0xE03C4 GLCDC 32-bit
  [31:24] GR1CLUT0[241].A, [23:16] GR1CLUT0[241].R, [15:8] GR1CLUT0[241].G, [7:0] GR1CLUT0[241].B
0xE03C8 GLCDC 32-bit
  [31:24] GR1CLUT0[242].A, [23:16] GR1CLUT0[242].R, [15:8] GR1CLUT0[242].G, [7:0] GR1CLUT0[242].B
0xE03CC GLCDC 32-bit
  [31:24] GR1CLUT0[243].A, [23:16] GR1CLUT0[243].R, [15:8] GR1CLUT0[243].G, [7:0] GR1CLUT0[243].B
0xE03D0 GLCDC 32-bit
  [31:24] GR1CLUT0[244].A, [23:16] GR1CLUT0[244].R, [15:8] GR1CLUT0[244].G, [7:0] GR1CLUT0[244].B
0xE03D4 GLCDC 32-bit
  [31:24] GR1CLUT0[245].A, [23:16] GR1CLUT0[245].R, [15:8] GR1CLUT0[245].G, [7:0] GR1CLUT0[245].B
0xE03D8 GLCDC 32-bit
  [31:24] GR1CLUT0[246].A, [23:16] GR1CLUT0[246].R, [15:8] GR1CLUT0[246].G, [7:0] GR1CLUT0[246].B
0xE03DC GLCDC 32-bit
  [31:24] GR1CLUT0[247].A, [23:16] GR1CLUT0[247].R, [15:8] GR1CLUT0[247].G, [7:0] GR1CLUT0[247].B
0xE03E0 GLCDC 32-bit
  [31:24] GR1CLUT0[248].A, [23:16] GR1CLUT0[248].R, [15:8] GR1CLUT0[248].G, [7:0] GR1CLUT0[248].B
0xE03E4 GLCDC 32-bit
  [31:24] GR1CLUT0[249].A, [23:16] GR1CLUT0[249].R, [15:8] GR1CLUT0[249].G, [7:0] GR1CLUT0[249].B
0xE03E8 GLCDC 32-bit
  [31:24] GR1CLUT0[250].A, [23:16] GR1CLUT0[250].R, [15:8] GR1CLUT0[250].G, [7:0] GR1CLUT0[250].B
0xE03EC GLCDC 32-bit
  [31:24] GR1CLUT0[251].A, [23:16] GR1CLUT0[251].R, [15:8] GR1CLUT0[251].G, [7:0] GR1CLUT0[251].B
0xE03F0 GLCDC 32-bit
  [31:24] GR1CLUT0[252].A, [23:16] GR1CLUT0[252].R, [15:8] GR1CLUT0[252].G, [7:0] GR1CLUT0[252].B
0xE03F4 GLCDC 32-bit
  [31:24] GR1CLUT0[253].A, [23:16] GR1CLUT0[253].R, [15:8] GR1CLUT0[253].G, [7:0] GR1CLUT0[253].B
0xE03F8 GLCDC 32-bit
  [31:24] GR1CLUT0[254].A, [23:16] GR1CLUT0[254].R, [15:8] GR1CLUT0[254].G, [7:0] GR1CLUT0[254].B
0xE03FC GLCDC 32-bit
  [31:24] GR1CLUT0[255].A, [23:16] GR1CLUT0[255].R, [15:8] GR1CLUT0[255].G, [7:0] GR1CLUT0[255].B
0xE0400 GLCDC 32-bit
  [31:24] GR1CLUT1[0].A, [23:16] GR1CLUT1[0].R, [15:8] GR1CLUT1[0].G, [7:0] GR1CLUT1[0].B
0xE0404 GLCDC 32-bit
  [31:24] GR1CLUT1[1].A, [23:16] GR1CLUT1[1].R, [15:8] GR1CLUT1[1].G, [7:0] GR1CLUT1[1].B
0xE0408 GLCDC 32-bit
  [31:24] GR1CLUT1[2].A, [23:16] GR1CLUT1[2].R, [15:8] GR1CLUT1[2].G, [7:0] GR1CLUT1[2].B
0xE040C GLCDC 32-bit
  [31:24] GR1CLUT1[3].A, [23:16] GR1CLUT1[3].R, [15:8] GR1CLUT1[3].G, [7:0] GR1CLUT1[3].B
0xE0410 GLCDC 32-bit
  [31:24] GR1CLUT1[4].A, [23:16] GR1CLUT1[4].R, [15:8] GR1CLUT1[4].G, [7:0] GR1CLUT1[4].B
0xE0414 GLCDC 32-bit
  [31:24] GR1CLUT1[5].A, [23:16] GR1CLUT1[5].R, [15:8] GR1CLUT1[5].G, [7:0] GR1CLUT1[5].B
0xE0418 GLCDC 32-bit
  [31:24] GR1CLUT1[6].A, [23:16] GR1CLUT1[6].R, [15:8] GR1CLUT1[6].G, [7:0] GR1CLUT1[6].B
0xE041C GLCDC 32-bit
  [31:24] GR1CLUT1[7].A, [23:16] GR1CLUT1[7].R, [15:8] GR1CLUT1[7].G, [7:0] GR1CLUT1[7].B
0xE0420 GLCDC 32-bit
  [31:24] GR1CLUT1[8].A, [23:16] GR1CLUT1[8].R, [15:8] GR1CLUT1[8].G, [7:0] GR1CLUT1[8].B
0xE0424 GLCDC 32-bit
  [31:24] GR1CLUT1[9].A, [23:16] GR1CLUT1[9].R, [15:8] GR1CLUT1[9].G, [7:0] GR1CLUT1[9].B
0xE0428 GLCDC 32-bit
  [31:24] GR1CLUT1[10].A, [23:16] GR1CLUT1[10].R, [15:8] GR1CLUT1[10].G, [7:0] GR1CLUT1[10].B
0xE042C GLCDC 32-bit
  [31:24] GR1CLUT1[11].A, [23:16] GR1CLUT1[11].R, [15:8] GR1CLUT1[11].G, [7:0] GR1CLUT1[11].B
0xE0430 GLCDC 32-bit
  [31:24] GR1CLUT1[12].A, [23:16] GR1CLUT1[12].R, [15:8] GR1CLUT1[12].G, [7:0] GR1CLUT1[12].B
0xE0434 GLCDC 32-bit
  [31:24] GR1CLUT1[13].A, [23:16] GR1CLUT1[13].R, [15:8] GR1CLUT1[13].G, [7:0] GR1CLUT1[13].B
0xE0438 GLCDC 32-bit
  [31:24] GR1CLUT1[14].A, [23:16] GR1CLUT1[14].R, [15:8] GR1CLUT1[14].G, [7:0] GR1CLUT1[14].B
0xE043C GLCDC 32-bit
  [31:24] GR1CLUT1[15].A, [23:16] GR1CLUT1[15].R, [15:8] GR1CLUT1[15].G, [7:0] GR1CLUT1[15].B
0xE0440 GLCDC 32-bit
  [31:24] GR1CLUT1[16].A, [23:16] GR1CLUT1[16].R, [15:8] GR1CLUT1[16].G, [7:0] GR1CLUT1[16].B
0xE0444 GLCDC 32-bit
  [31:24] GR1CLUT1[17].A, [23:16] GR1CLUT1[17].R, [15:8] GR1CLUT1[17].G, [7:0] GR1CLUT1[17].B
0xE0448 GLCDC 32-bit
  [31:24] GR1CLUT1[18].A, [23:16] GR1CLUT1[18].R, [15:8] GR1CLUT1[18].G, [7:0] GR1CLUT1[18].B
0xE044C GLCDC 32-bit
  [31:24] GR1CLUT1[19].A, [23:16] GR1CLUT1[19].R, [15:8] GR1CLUT1[19].G, [7:0] GR1CLUT1[19].B
0xE0450 GLCDC 32-bit
  [31:24] GR1CLUT1[20].A, [23:16] GR1CLUT1[20].R, [15:8] GR1CLUT1[20].G, [7:0] GR1CLUT1[20].B
0xE0454 GLCDC 32-bit
  [31:24] GR1CLUT1[21].A, [23:16] GR1CLUT1[21].R, [15:8] GR1CLUT1[21].G, [7:0] GR1CLUT1[21].B
0xE0458 GLCDC 32-bit
  [31:24] GR1CLUT1[22].A, [23:16] GR1CLUT1[22].R, [15:8] GR1CLUT1[22].G, [7:0] GR1CLUT1[22].B
0xE045C GLCDC 32-bit
  [31:24] GR1CLUT1[23].A, [23:16] GR1CLUT1[23].R, [15:8] GR1CLUT1[23].G, [7:0] GR1CLUT1[23].B
0xE0460 GLCDC 32-bit
  [31:24] GR1CLUT1[24].A, [23:16] GR1CLUT1[24].R, [15:8] GR1CLUT1[24].G, [7:0] GR1CLUT1[24].B
0xE0464 GLCDC 32-bit
  [31:24] GR1CLUT1[25].A, [23:16] GR1CLUT1[25].R, [15:8] GR1CLUT1[25].G, [7:0] GR1CLUT1[25].B
0xE0468 GLCDC 32-bit
  [31:24] GR1CLUT1[26].A, [23:16] GR1CLUT1[26].R, [15:8] GR1CLUT1[26].G, [7:0] GR1CLUT1[26].B
0xE046C GLCDC 32-bit
  [31:24] GR1CLUT1[27].A, [23:16] GR1CLUT1[27].R, [15:8] GR1CLUT1[27].G, [7:0] GR1CLUT1[27].B
0xE0470 GLCDC 32-bit
  [31:24] GR1CLUT1[28].A, [23:16] GR1CLUT1[28].R, [15:8] GR1CLUT1[28].G, [7:0] GR1CLUT1[28].B
0xE0474 GLCDC 32-bit
  [31:24] GR1CLUT1[29].A, [23:16] GR1CLUT1[29].R, [15:8] GR1CLUT1[29].G, [7:0] GR1CLUT1[29].B
0xE0478 GLCDC 32-bit
  [31:24] GR1CLUT1[30].A, [23:16] GR1CLUT1[30].R, [15:8] GR1CLUT1[30].G, [7:0] GR1CLUT1[30].B
0xE047C GLCDC 32-bit
  [31:24] GR1CLUT1[31].A, [23:16] GR1CLUT1[31].R, [15:8] GR1CLUT1[31].G, [7:0] GR1CLUT1[31].B
0xE0480 GLCDC 32-bit
  [31:24] GR1CLUT1[32].A, [23:16] GR1CLUT1[32].R, [15:8] GR1CLUT1[32].G, [7:0] GR1CLUT1[32].B
0xE0484 GLCDC 32-bit
  [31:24] GR1CLUT1[33].A, [23:16] GR1CLUT1[33].R, [15:8] GR1CLUT1[33].G, [7:0] GR1CLUT1[33].B
0xE0488 GLCDC 32-bit
  [31:24] GR1CLUT1[34].A, [23:16] GR1CLUT1[34].R, [15:8] GR1CLUT1[34].G, [7:0] GR1CLUT1[34].B
0xE048C GLCDC 32-bit
  [31:24] GR1CLUT1[35].A, [23:16] GR1CLUT1[35].R, [15:8] GR1CLUT1[35].G, [7:0] GR1CLUT1[35].B
0xE0490 GLCDC 32-bit
  [31:24] GR1CLUT1[36].A, [23:16] GR1CLUT1[36].R, [15:8] GR1CLUT1[36].G, [7:0] GR1CLUT1[36].B
0xE0494 GLCDC 32-bit
  [31:24] GR1CLUT1[37].A, [23:16] GR1CLUT1[37].R, [15:8] GR1CLUT1[37].G, [7:0] GR1CLUT1[37].B
0xE0498 GLCDC 32-bit
  [31:24] GR1CLUT1[38].A, [23:16] GR1CLUT1[38].R, [15:8] GR1CLUT1[38].G, [7:0] GR1CLUT1[38].B
0xE049C GLCDC 32-bit
  [31:24] GR1CLUT1[39].A, [23:16] GR1CLUT1[39].R, [15:8] GR1CLUT1[39].G, [7:0] GR1CLUT1[39].B
0xE04A0 GLCDC 32-bit
  [31:24] GR1CLUT1[40].A, [23:16] GR1CLUT1[40].R, [15:8] GR1CLUT1[40].G, [7:0] GR1CLUT1[40].B
0xE04A4 GLCDC 32-bit
  [31:24] GR1CLUT1[41].A, [23:16] GR1CLUT1[41].R, [15:8] GR1CLUT1[41].G, [7:0] GR1CLUT1[41].B
0xE04A8 GLCDC 32-bit
  [31:24] GR1CLUT1[42].A, [23:16] GR1CLUT1[42].R, [15:8] GR1CLUT1[42].G, [7:0] GR1CLUT1[42].B
0xE04AC GLCDC 32-bit
  [31:24] GR1CLUT1[43].A, [23:16] GR1CLUT1[43].R, [15:8] GR1CLUT1[43].G, [7:0] GR1CLUT1[43].B
0xE04B0 GLCDC 32-bit
  [31:24] GR1CLUT1[44].A, [23:16] GR1CLUT1[44].R, [15:8] GR1CLUT1[44].G, [7:0] GR1CLUT1[44].B
0xE04B4 GLCDC 32-bit
  [31:24] GR1CLUT1[45].A, [23:16] GR1CLUT1[45].R, [15:8] GR1CLUT1[45].G, [7:0] GR1CLUT1[45].B
0xE04B8 GLCDC 32-bit
  [31:24] GR1CLUT1[46].A, [23:16] GR1CLUT1[46].R, [15:8] GR1CLUT1[46].G, [7:0] GR1CLUT1[46].B
0xE04BC GLCDC 32-bit
  [31:24] GR1CLUT1[47].A, [23:16] GR1CLUT1[47].R, [15:8] GR1CLUT1[47].G, [7:0] GR1CLUT1[47].B
0xE04C0 GLCDC 32-bit
  [31:24] GR1CLUT1[48].A, [23:16] GR1CLUT1[48].R, [15:8] GR1CLUT1[48].G, [7:0] GR1CLUT1[48].B
0xE04C4 GLCDC 32-bit
  [31:24] GR1CLUT1[49].A, [23:16] GR1CLUT1[49].R, [15:8] GR1CLUT1[49].G, [7:0] GR1CLUT1[49].B
0xE04C8 GLCDC 32-bit
  [31:24] GR1CLUT1[50].A, [23:16] GR1CLUT1[50].R, [15:8] GR1CLUT1[50].G, [7:0] GR1CLUT1[50].B
0xE04CC GLCDC 32-bit
  [31:24] GR1CLUT1[51].A, [23:16] GR1CLUT1[51].R, [15:8] GR1CLUT1[51].G, [7:0] GR1CLUT1[51].B
0xE04D0 GLCDC 32-bit
  [31:24] GR1CLUT1[52].A, [23:16] GR1CLUT1[52].R, [15:8] GR1CLUT1[52].G, [7:0] GR1CLUT1[52].B
0xE04D4 GLCDC 32-bit
  [31:24] GR1CLUT1[53].A, [23:16] GR1CLUT1[53].R, [15:8] GR1CLUT1[53].G, [7:0] GR1CLUT1[53].B
0xE04D8 GLCDC 32-bit
  [31:24] GR1CLUT1[54].A, [23:16] GR1CLUT1[54].R, [15:8] GR1CLUT1[54].G, [7:0] GR1CLUT1[54].B
0xE04DC GLCDC 32-bit
  [31:24] GR1CLUT1[55].A, [23:16] GR1CLUT1[55].R, [15:8] GR1CLUT1[55].G, [7:0] GR1CLUT1[55].B
0xE04E0 GLCDC 32-bit
  [31:24] GR1CLUT1[56].A, [23:16] GR1CLUT1[56].R, [15:8] GR1CLUT1[56].G, [7:0] GR1CLUT1[56].B
0xE04E4 GLCDC 32-bit
  [31:24] GR1CLUT1[57].A, [23:16] GR1CLUT1[57].R, [15:8] GR1CLUT1[57].G, [7:0] GR1CLUT1[57].B
0xE04E8 GLCDC 32-bit
  [31:24] GR1CLUT1[58].A, [23:16] GR1CLUT1[58].R, [15:8] GR1CLUT1[58].G, [7:0] GR1CLUT1[58].B
0xE04EC GLCDC 32-bit
  [31:24] GR1CLUT1[59].A, [23:16] GR1CLUT1[59].R, [15:8] GR1CLUT1[59].G, [7:0] GR1CLUT1[59].B
0xE04F0 GLCDC 32-bit
  [31:24] GR1CLUT1[60].A, [23:16] GR1CLUT1[60].R, [15:8] GR1CLUT1[60].G, [7:0] GR1CLUT1[60].B
0xE04F4 GLCDC 32-bit
  [31:24] GR1CLUT1[61].A, [23:16] GR1CLUT1[61].R, [15:8] GR1CLUT1[61].G, [7:0] GR1CLUT1[61].B
0xE04F8 GLCDC 32-bit
  [31:24] GR1CLUT1[62].A, [23:16] GR1CLUT1[62].R, [15:8] GR1CLUT1[62].G, [7:0] GR1CLUT1[62].B
0xE04FC GLCDC 32-bit
  [31:24] GR1CLUT1[63].A, [23:16] GR1CLUT1[63].R, [15:8] GR1CLUT1[63].G, [7:0] GR1CLUT1[63].B
0xE0500 GLCDC 32-bit
  [31:24] GR1CLUT1[64].A, [23:16] GR1CLUT1[64].R, [15:8] GR1CLUT1[64].G, [7:0] GR1CLUT1[64].B
0xE0504 GLCDC 32-bit
  [31:24] GR1CLUT1[65].A, [23:16] GR1CLUT1[65].R, [15:8] GR1CLUT1[65].G, [7:0] GR1CLUT1[65].B
0xE0508 GLCDC 32-bit
  [31:24] GR1CLUT1[66].A, [23:16] GR1CLUT1[66].R, [15:8] GR1CLUT1[66].G, [7:0] GR1CLUT1[66].B
0xE050C GLCDC 32-bit
  [31:24] GR1CLUT1[67].A, [23:16] GR1CLUT1[67].R, [15:8] GR1CLUT1[67].G, [7:0] GR1CLUT1[67].B
0xE0510 GLCDC 32-bit
  [31:24] GR1CLUT1[68].A, [23:16] GR1CLUT1[68].R, [15:8] GR1CLUT1[68].G, [7:0] GR1CLUT1[68].B
0xE0514 GLCDC 32-bit
  [31:24] GR1CLUT1[69].A, [23:16] GR1CLUT1[69].R, [15:8] GR1CLUT1[69].G, [7:0] GR1CLUT1[69].B
0xE0518 GLCDC 32-bit
  [31:24] GR1CLUT1[70].A, [23:16] GR1CLUT1[70].R, [15:8] GR1CLUT1[70].G, [7:0] GR1CLUT1[70].B
0xE051C GLCDC 32-bit
  [31:24] GR1CLUT1[71].A, [23:16] GR1CLUT1[71].R, [15:8] GR1CLUT1[71].G, [7:0] GR1CLUT1[71].B
0xE0520 GLCDC 32-bit
  [31:24] GR1CLUT1[72].A, [23:16] GR1CLUT1[72].R, [15:8] GR1CLUT1[72].G, [7:0] GR1CLUT1[72].B
0xE0524 GLCDC 32-bit
  [31:24] GR1CLUT1[73].A, [23:16] GR1CLUT1[73].R, [15:8] GR1CLUT1[73].G, [7:0] GR1CLUT1[73].B
0xE0528 GLCDC 32-bit
  [31:24] GR1CLUT1[74].A, [23:16] GR1CLUT1[74].R, [15:8] GR1CLUT1[74].G, [7:0] GR1CLUT1[74].B
0xE052C GLCDC 32-bit
  [31:24] GR1CLUT1[75].A, [23:16] GR1CLUT1[75].R, [15:8] GR1CLUT1[75].G, [7:0] GR1CLUT1[75].B
0xE0530 GLCDC 32-bit
  [31:24] GR1CLUT1[76].A, [23:16] GR1CLUT1[76].R, [15:8] GR1CLUT1[76].G, [7:0] GR1CLUT1[76].B
0xE0534 GLCDC 32-bit
  [31:24] GR1CLUT1[77].A, [23:16] GR1CLUT1[77].R, [15:8] GR1CLUT1[77].G, [7:0] GR1CLUT1[77].B
0xE0538 GLCDC 32-bit
  [31:24] GR1CLUT1[78].A, [23:16] GR1CLUT1[78].R, [15:8] GR1CLUT1[78].G, [7:0] GR1CLUT1[78].B
0xE053C GLCDC 32-bit
  [31:24] GR1CLUT1[79].A, [23:16] GR1CLUT1[79].R, [15:8] GR1CLUT1[79].G, [7:0] GR1CLUT1[79].B
0xE0540 GLCDC 32-bit
  [31:24] GR1CLUT1[80].A, [23:16] GR1CLUT1[80].R, [15:8] GR1CLUT1[80].G, [7:0] GR1CLUT1[80].B
0xE0544 GLCDC 32-bit
  [31:24] GR1CLUT1[81].A, [23:16] GR1CLUT1[81].R, [15:8] GR1CLUT1[81].G, [7:0] GR1CLUT1[81].B
0xE0548 GLCDC 32-bit
  [31:24] GR1CLUT1[82].A, [23:16] GR1CLUT1[82].R, [15:8] GR1CLUT1[82].G, [7:0] GR1CLUT1[82].B
0xE054C GLCDC 32-bit
  [31:24] GR1CLUT1[83].A, [23:16] GR1CLUT1[83].R, [15:8] GR1CLUT1[83].G, [7:0] GR1CLUT1[83].B
0xE0550 GLCDC 32-bit
  [31:24] GR1CLUT1[84].A, [23:16] GR1CLUT1[84].R, [15:8] GR1CLUT1[84].G, [7:0] GR1CLUT1[84].B
0xE0554 GLCDC 32-bit
  [31:24] GR1CLUT1[85].A, [23:16] GR1CLUT1[85].R, [15:8] GR1CLUT1[85].G, [7:0] GR1CLUT1[85].B
0xE0558 GLCDC 32-bit
  [31:24] GR1CLUT1[86].A, [23:16] GR1CLUT1[86].R, [15:8] GR1CLUT1[86].G, [7:0] GR1CLUT1[86].B
0xE055C GLCDC 32-bit
  [31:24] GR1CLUT1[87].A, [23:16] GR1CLUT1[87].R, [15:8] GR1CLUT1[87].G, [7:0] GR1CLUT1[87].B
0xE0560 GLCDC 32-bit
  [31:24] GR1CLUT1[88].A, [23:16] GR1CLUT1[88].R, [15:8] GR1CLUT1[88].G, [7:0] GR1CLUT1[88].B
0xE0564 GLCDC 32-bit
  [31:24] GR1CLUT1[89].A, [23:16] GR1CLUT1[89].R, [15:8] GR1CLUT1[89].G, [7:0] GR1CLUT1[89].B
0xE0568 GLCDC 32-bit
  [31:24] GR1CLUT1[90].A, [23:16] GR1CLUT1[90].R, [15:8] GR1CLUT1[90].G, [7:0] GR1CLUT1[90].B
0xE056C GLCDC 32-bit
  [31:24] GR1CLUT1[91].A, [23:16] GR1CLUT1[91].R, [15:8] GR1CLUT1[91].G, [7:0] GR1CLUT1[91].B
0xE0570 GLCDC 32-bit
  [31:24] GR1CLUT1[92].A, [23:16] GR1CLUT1[92].R, [15:8] GR1CLUT1[92].G, [7:0] GR1CLUT1[92].B
0xE0574 GLCDC 32-bit
  [31:24] GR1CLUT1[93].A, [23:16] GR1CLUT1[93].R, [15:8] GR1CLUT1[93].G, [7:0] GR1CLUT1[93].B
0xE0578 GLCDC 32-bit
  [31:24] GR1CLUT1[94].A, [23:16] GR1CLUT1[94].R, [15:8] GR1CLUT1[94].G, [7:0] GR1CLUT1[94].B
0xE057C GLCDC 32-bit
  [31:24] GR1CLUT1[95].A, [23:16] GR1CLUT1[95].R, [15:8] GR1CLUT1[95].G, [7:0] GR1CLUT1[95].B
0xE0580 GLCDC 32-bit
  [31:24] GR1CLUT1[96].A, [23:16] GR1CLUT1[96].R, [15:8] GR1CLUT1[96].G, [7:0] GR1CLUT1[96].B
0xE0584 GLCDC 32-bit
  [31:24] GR1CLUT1[97].A, [23:16] GR1CLUT1[97].R, [15:8] GR1CLUT1[97].G, [7:0] GR1CLUT1[97].B
0xE0588 GLCDC 32-bit
  [31:24] GR1CLUT1[98].A, [23:16] GR1CLUT1[98].R, [15:8] GR1CLUT1[98].G, [7:0] GR1CLUT1[98].B
0xE058C GLCDC 32-bit
  [31:24] GR1CLUT1[99].A, [23:16] GR1CLUT1[99].R, [15:8] GR1CLUT1[99].G, [7:0] GR1CLUT1[99].B
0xE0590 GLCDC 32-bit
  [31:24] GR1CLUT1[100].A, [23:16] GR1CLUT1[100].R, [15:8] GR1CLUT1[100].G, [7:0] GR1CLUT1[100].B
0xE0594 GLCDC 32-bit
  [31:24] GR1CLUT1[101].A, [23:16] GR1CLUT1[101].R, [15:8] GR1CLUT1[101].G, [7:0] GR1CLUT1[101].B
0xE0598 GLCDC 32-bit
  [31:24] GR1CLUT1[102].A, [23:16] GR1CLUT1[102].R, [15:8] GR1CLUT1[102].G, [7:0] GR1CLUT1[102].B
0xE059C GLCDC 32-bit
  [31:24] GR1CLUT1[103].A, [23:16] GR1CLUT1[103].R, [15:8] GR1CLUT1[103].G, [7:0] GR1CLUT1[103].B
0xE05A0 GLCDC 32-bit
  [31:24] GR1CLUT1[104].A, [23:16] GR1CLUT1[104].R, [15:8] GR1CLUT1[104].G, [7:0] GR1CLUT1[104].B
0xE05A4 GLCDC 32-bit
  [31:24] GR1CLUT1[105].A, [23:16] GR1CLUT1[105].R, [15:8] GR1CLUT1[105].G, [7:0] GR1CLUT1[105].B
0xE05A8 GLCDC 32-bit
  [31:24] GR1CLUT1[106].A, [23:16] GR1CLUT1[106].R, [15:8] GR1CLUT1[106].G, [7:0] GR1CLUT1[106].B
0xE05AC GLCDC 32-bit
  [31:24] GR1CLUT1[107].A, [23:16] GR1CLUT1[107].R, [15:8] GR1CLUT1[107].G, [7:0] GR1CLUT1[107].B
0xE05B0 GLCDC 32-bit
  [31:24] GR1CLUT1[108].A, [23:16] GR1CLUT1[108].R, [15:8] GR1CLUT1[108].G, [7:0] GR1CLUT1[108].B
0xE05B4 GLCDC 32-bit
  [31:24] GR1CLUT1[109].A, [23:16] GR1CLUT1[109].R, [15:8] GR1CLUT1[109].G, [7:0] GR1CLUT1[109].B
0xE05B8 GLCDC 32-bit
  [31:24] GR1CLUT1[110].A, [23:16] GR1CLUT1[110].R, [15:8] GR1CLUT1[110].G, [7:0] GR1CLUT1[110].B
0xE05BC GLCDC 32-bit
  [31:24] GR1CLUT1[111].A, [23:16] GR1CLUT1[111].R, [15:8] GR1CLUT1[111].G, [7:0] GR1CLUT1[111].B
0xE05C0 GLCDC 32-bit
  [31:24] GR1CLUT1[112].A, [23:16] GR1CLUT1[112].R, [15:8] GR1CLUT1[112].G, [7:0] GR1CLUT1[112].B
0xE05C4 GLCDC 32-bit
  [31:24] GR1CLUT1[113].A, [23:16] GR1CLUT1[113].R, [15:8] GR1CLUT1[113].G, [7:0] GR1CLUT1[113].B
0xE05C8 GLCDC 32-bit
  [31:24] GR1CLUT1[114].A, [23:16] GR1CLUT1[114].R, [15:8] GR1CLUT1[114].G, [7:0] GR1CLUT1[114].B
0xE05CC GLCDC 32-bit
  [31:24] GR1CLUT1[115].A, [23:16] GR1CLUT1[115].R, [15:8] GR1CLUT1[115].G, [7:0] GR1CLUT1[115].B
0xE05D0 GLCDC 32-bit
  [31:24] GR1CLUT1[116].A, [23:16] GR1CLUT1[116].R, [15:8] GR1CLUT1[116].G, [7:0] GR1CLUT1[116].B
0xE05D4 GLCDC 32-bit
  [31:24] GR1CLUT1[117].A, [23:16] GR1CLUT1[117].R, [15:8] GR1CLUT1[117].G, [7:0] GR1CLUT1[117].B
0xE05D8 GLCDC 32-bit
  [31:24] GR1CLUT1[118].A, [23:16] GR1CLUT1[118].R, [15:8] GR1CLUT1[118].G, [7:0] GR1CLUT1[118].B
0xE05DC GLCDC 32-bit
  [31:24] GR1CLUT1[119].A, [23:16] GR1CLUT1[119].R, [15:8] GR1CLUT1[119].G, [7:0] GR1CLUT1[119].B
0xE05E0 GLCDC 32-bit
  [31:24] GR1CLUT1[120].A, [23:16] GR1CLUT1[120].R, [15:8] GR1CLUT1[120].G, [7:0] GR1CLUT1[120].B
0xE05E4 GLCDC 32-bit
  [31:24] GR1CLUT1[121].A, [23:16] GR1CLUT1[121].R, [15:8] GR1CLUT1[121].G, [7:0] GR1CLUT1[121].B
0xE05E8 GLCDC 32-bit
  [31:24] GR1CLUT1[122].A, [23:16] GR1CLUT1[122].R, [15:8] GR1CLUT1[122].G, [7:0] GR1CLUT1[122].B
0xE05EC GLCDC 32-bit
  [31:24] GR1CLUT1[123].A, [23:16] GR1CLUT1[123].R, [15:8] GR1CLUT1[123].G, [7:0] GR1CLUT1[123].B
0xE05F0 GLCDC 32-bit
  [31:24] GR1CLUT1[124].A, [23:16] GR1CLUT1[124].R, [15:8] GR1CLUT1[124].G, [7:0] GR1CLUT1[124].B
0xE05F4 GLCDC 32-bit
  [31:24] GR1CLUT1[125].A, [23:16] GR1CLUT1[125].R, [15:8] GR1CLUT1[125].G, [7:0] GR1CLUT1[125].B
0xE05F8 GLCDC 32-bit
  [31:24] GR1CLUT1[126].A, [23:16] GR1CLUT1[126].R, [15:8] GR1CLUT1[126].G, [7:0] GR1CLUT1[126].B
0xE05FC GLCDC 32-bit
  [31:24] GR1CLUT1[127].A, [23:16] GR1CLUT1[127].R, [15:8] GR1CLUT1[127].G, [7:0] GR1CLUT1[127].B
0xE0600 GLCDC 32-bit
  [31:24] GR1CLUT1[128].A, [23:16] GR1CLUT1[128].R, [15:8] GR1CLUT1[128].G, [7:0] GR1CLUT1[128].B
0xE0604 GLCDC 32-bit
  [31:24] GR1CLUT1[129].A, [23:16] GR1CLUT1[129].R, [15:8] GR1CLUT1[129].G, [7:0] GR1CLUT1[129].B
0xE0608 GLCDC 32-bit
  [31:24] GR1CLUT1[130].A, [23:16] GR1CLUT1[130].R, [15:8] GR1CLUT1[130].G, [7:0] GR1CLUT1[130].B
0xE060C GLCDC 32-bit
  [31:24] GR1CLUT1[131].A, [23:16] GR1CLUT1[131].R, [15:8] GR1CLUT1[131].G, [7:0] GR1CLUT1[131].B
0xE0610 GLCDC 32-bit
  [31:24] GR1CLUT1[132].A, [23:16] GR1CLUT1[132].R, [15:8] GR1CLUT1[132].G, [7:0] GR1CLUT1[132].B
0xE0614 GLCDC 32-bit
  [31:24] GR1CLUT1[133].A, [23:16] GR1CLUT1[133].R, [15:8] GR1CLUT1[133].G, [7:0] GR1CLUT1[133].B
0xE0618 GLCDC 32-bit
  [31:24] GR1CLUT1[134].A, [23:16] GR1CLUT1[134].R, [15:8] GR1CLUT1[134].G, [7:0] GR1CLUT1[134].B
0xE061C GLCDC 32-bit
  [31:24] GR1CLUT1[135].A, [23:16] GR1CLUT1[135].R, [15:8] GR1CLUT1[135].G, [7:0] GR1CLUT1[135].B
0xE0620 GLCDC 32-bit
  [31:24] GR1CLUT1[136].A, [23:16] GR1CLUT1[136].R, [15:8] GR1CLUT1[136].G, [7:0] GR1CLUT1[136].B
0xE0624 GLCDC 32-bit
  [31:24] GR1CLUT1[137].A, [23:16] GR1CLUT1[137].R, [15:8] GR1CLUT1[137].G, [7:0] GR1CLUT1[137].B
0xE0628 GLCDC 32-bit
  [31:24] GR1CLUT1[138].A, [23:16] GR1CLUT1[138].R, [15:8] GR1CLUT1[138].G, [7:0] GR1CLUT1[138].B
0xE062C GLCDC 32-bit
  [31:24] GR1CLUT1[139].A, [23:16] GR1CLUT1[139].R, [15:8] GR1CLUT1[139].G, [7:0] GR1CLUT1[139].B
0xE0630 GLCDC 32-bit
  [31:24] GR1CLUT1[140].A, [23:16] GR1CLUT1[140].R, [15:8] GR1CLUT1[140].G, [7:0] GR1CLUT1[140].B
0xE0634 GLCDC 32-bit
  [31:24] GR1CLUT1[141].A, [23:16] GR1CLUT1[141].R, [15:8] GR1CLUT1[141].G, [7:0] GR1CLUT1[141].B
0xE0638 GLCDC 32-bit
  [31:24] GR1CLUT1[142].A, [23:16] GR1CLUT1[142].R, [15:8] GR1CLUT1[142].G, [7:0] GR1CLUT1[142].B
0xE063C GLCDC 32-bit
  [31:24] GR1CLUT1[143].A, [23:16] GR1CLUT1[143].R, [15:8] GR1CLUT1[143].G, [7:0] GR1CLUT1[143].B
0xE0640 GLCDC 32-bit
  [31:24] GR1CLUT1[144].A, [23:16] GR1CLUT1[144].R, [15:8] GR1CLUT1[144].G, [7:0] GR1CLUT1[144].B
0xE0644 GLCDC 32-bit
  [31:24] GR1CLUT1[145].A, [23:16] GR1CLUT1[145].R, [15:8] GR1CLUT1[145].G, [7:0] GR1CLUT1[145].B
0xE0648 GLCDC 32-bit
  [31:24] GR1CLUT1[146].A, [23:16] GR1CLUT1[146].R, [15:8] GR1CLUT1[146].G, [7:0] GR1CLUT1[146].B
0xE064C GLCDC 32-bit
  [31:24] GR1CLUT1[147].A, [23:16] GR1CLUT1[147].R, [15:8] GR1CLUT1[147].G, [7:0] GR1CLUT1[147].B
0xE0650 GLCDC 32-bit
  [31:24] GR1CLUT1[148].A, [23:16] GR1CLUT1[148].R, [15:8] GR1CLUT1[148].G, [7:0] GR1CLUT1[148].B
0xE0654 GLCDC 32-bit
  [31:24] GR1CLUT1[149].A, [23:16] GR1CLUT1[149].R, [15:8] GR1CLUT1[149].G, [7:0] GR1CLUT1[149].B
0xE0658 GLCDC 32-bit
  [31:24] GR1CLUT1[150].A, [23:16] GR1CLUT1[150].R, [15:8] GR1CLUT1[150].G, [7:0] GR1CLUT1[150].B
0xE065C GLCDC 32-bit
  [31:24] GR1CLUT1[151].A, [23:16] GR1CLUT1[151].R, [15:8] GR1CLUT1[151].G, [7:0] GR1CLUT1[151].B
0xE0660 GLCDC 32-bit
  [31:24] GR1CLUT1[152].A, [23:16] GR1CLUT1[152].R, [15:8] GR1CLUT1[152].G, [7:0] GR1CLUT1[152].B
0xE0664 GLCDC 32-bit
  [31:24] GR1CLUT1[153].A, [23:16] GR1CLUT1[153].R, [15:8] GR1CLUT1[153].G, [7:0] GR1CLUT1[153].B
0xE0668 GLCDC 32-bit
  [31:24] GR1CLUT1[154].A, [23:16] GR1CLUT1[154].R, [15:8] GR1CLUT1[154].G, [7:0] GR1CLUT1[154].B
0xE066C GLCDC 32-bit
  [31:24] GR1CLUT1[155].A, [23:16] GR1CLUT1[155].R, [15:8] GR1CLUT1[155].G, [7:0] GR1CLUT1[155].B
0xE0670 GLCDC 32-bit
  [31:24] GR1CLUT1[156].A, [23:16] GR1CLUT1[156].R, [15:8] GR1CLUT1[156].G, [7:0] GR1CLUT1[156].B
